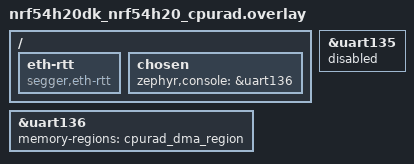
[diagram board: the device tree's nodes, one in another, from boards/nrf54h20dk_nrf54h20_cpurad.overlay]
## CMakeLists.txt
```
#
# Copyright (c) 2021 Nordic Semiconductor ASA
#
# SPDX-License-Identifier: LicenseRef-Nordic-5-Clause
#

cmake_minimum_required(VERSION 3.20.0)

find_package(Zephyr REQUIRED HINTS $ENV{ZEPHYR_BASE})

project(psa_tls_sample)

zephyr_include_directories(src ${COMMON_DIR})
target_include_directories(app PUBLIC ./include)
target_sources(app PRIVATE src/main.c
                           src/psa_tls_common.c)

if(CONFIG_BUILD_WITH_TFM)
  set(TLS_SRC_PATH "non-secure")
else()
  set(TLS_SRC_PATH "secure")
endif()

if(CONFIG_PSA_TLS_SAMPLE_TYPE_SERVER)
  target_sources(app PRIVATE src/${TLS_SRC_PATH}/psa_tls_credentials_server.c)
  if(CONFIG_NET_SOCKETS_ENABLE_DTLS)
    target_sources(app PRIVATE src/psa_dtls_functions_server.c)
  else()
    target_sources(app PRIVATE src/psa_tls_functions_server.c)
  endif()
else()
  target_sources(app PRIVATE src/${TLS_SRC_PATH}/psa_tls_credentials_client.c)
  if(CONFIG_NET_SOCKETS_ENABLE_DTLS)
    target_sources(app PRIVATE src/psa_dtls_functions_client.c)
  else()
    target_sources(app PRIVATE src/psa_tls_functions_client.c)
  endif()
endif()

set(gen_dir ${ZEPHYR_BINARY_DIR}/include/generated/)

if(CONFIG_PSA_WANT_ECC_SECP_R1_256)
  set(CURVE "_secp256r1")
elseif(CONFIG_PSA_WANT_ECC_SECP_R1_384)
  set(CURVE "_secp384r1")
endif()

if(CONFIG_PSA_TLS_CERTIFICATE_TYPE_RSA)
  set(CTYPE "rsa")
  set(CURVE "")
elseif(CONFIG_PSA_TLS_CERTIFICATE_TYPE_ECDSA)
  set(CTYPE "ec")
endif()


foreach(inc_file
  root-cert
  server-cert
  server-cert-key
)
  set(modified_inc_file "${CTYPE}-${inc_file}${CURVE}.der")
  generate_inc_file_for_target(
    app
    certs/${modified_inc_file}
    ${gen_dir}/${inc_file}.der.inc
  )
endforeach()
```

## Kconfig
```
#
# Copyright (c) 2021 Nordic Semiconductor
#
# SPDX-License-Identifier: LicenseRef-Nordic-5-Clause
#

source "Kconfig.zephyr"

menu "PSA TLS sample"

choice PSA_TLS_CERTIFICATE_TYPE
	prompt "RSA or ECDSA certifcates"
	default PSA_TLS_CERTIFICATE_TYPE_ECDSA

config PSA_TLS_CERTIFICATE_TYPE_RSA
	bool "Use RSA certificate in PSA TLS sample"
	help
	  Enable RSA certificates when testing ciphers that supports RSA for authentication.

config PSA_TLS_CERTIFICATE_TYPE_ECDSA
	bool "Use ECDSA certificate in PSA TLS sample"
	help
	  Enable ECDSA certificates when testing ciphers that supports ECDSA for authentication.

endchoice

choice PSA_TLS_SAMPLE_TYPE
	prompt "Server or Client selection"
	default PSA_TLS_SAMPLE_TYPE_SERVER

config PSA_TLS_SAMPLE_TYPE_SERVER
	bool "Enable Server functionality in PSA TLS sample"

config PSA_TLS_SAMPLE_TYPE_CLIENT
	bool "Enable Client functionality in PSA TLS sample"

endchoice

config NET_CONFIG_MY_IPV4_ADDR
	default "192.0.2.1" if PSA_TLS_SAMPLE_TYPE_SERVER
	default "192.0.2.2" if PSA_TLS_SAMPLE_TYPE_CLIENT

config NET_CONFIG_PEER_IPV4_ADDR
	default "192.0.2.2" if PSA_TLS_SAMPLE_TYPE_SERVER
	default "192.0.2.1" if PSA_TLS_SAMPLE_TYPE_CLIENT

endmenu
```

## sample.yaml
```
sample:
  description: |
    This app provides an example of performing TLS handshake as either server or client
  name: TLS Sample
tests:
  ################################################################################
  ## PSA APIs with Cryptocell and Oberon
  ################################################################################
  sample.psa_tls.tls_server.ecdsa.cc3xx_oberon:
    sysbuild: true
    build_only: true
    extra_args:
      EXTRA_CONF_FILE="overlays/server.conf;overlays/ecdsa.conf;overlays/cc3xx-oberon-psa.conf"
    platform_allow:
      - nrf5340dk/nrf5340/cpuapp
      - nrf9160dk/nrf9160
      - nrf5340dk/nrf5340/cpuapp/ns
      - nrf9160dk/nrf9160/ns
      - nrf9161dk/nrf9161
      - nrf9161dk/nrf9161/ns
      - nrf9151dk/nrf9151
      - nrf9151dk/nrf9151/ns
    integration_platforms:
      - nrf5340dk/nrf5340/cpuapp
      - nrf5340dk/nrf5340/cpuapp/ns
      - nrf9160dk/nrf9160
      - nrf9160dk/nrf9160/ns
      - nrf9161dk/nrf9161
      - nrf9161dk/nrf9161/ns
      - nrf9151dk/nrf9151
      - nrf9151dk/nrf9151/ns
    tags:
      - ci_build
      - cc3xx_oberon
      - sysbuild
      - ci_samples_crypto
  sample.psa_tls.dtls_server.ecdsa.cc3xx_oberon:
    sysbuild: true
    build_only: true
    extra_args:
      EXTRA_CONF_FILE="overlays/server.conf;overlays/ecdsa.conf;overlays/cc3xx-oberon-psa.conf;overlays/dtls.conf"
    platform_allow:
      - nrf5340dk/nrf5340/cpuapp
      - nrf5340dk/nrf5340/cpuapp/ns
      - nrf9160dk/nrf9160
      - nrf9160dk/nrf9160/ns
      - nrf9161dk/nrf9161
      - nrf9161dk/nrf9161/ns
      - nrf9151dk/nrf9151
      - nrf9151dk/nrf9151/ns
    integration_platforms:
      - nrf5340dk/nrf5340/cpuapp
      - nrf5340dk/nrf5340/cpuapp/ns
      - nrf9160dk/nrf9160
      - nrf9160dk/nrf9160/ns
      - nrf9161dk/nrf9161
      - nrf9161dk/nrf9161/ns
      - nrf9151dk/nrf9151
      - nrf9151dk/nrf9151/ns
    tags:
      - ci_build
      - dtls
      - cc3xx_oberon
      - sysbuild
      - ci_samples_crypto
  sample.psa_tls.tls_client.ecdsa.cc3xx_oberon:
    sysbuild: true
    build_only: true
    extra_args:
      EXTRA_CONF_FILE="overlays/client.conf;overlays/ecdsa.conf;overlays/cc3xx-oberon-psa.conf"
    platform_allow:
      - nrf5340dk/nrf5340/cpuapp
      - nrf5340dk/nrf5340/cpuapp/ns
      - nrf9160dk/nrf9160
      - nrf9160dk/nrf9160/ns
      - nrf9161dk/nrf9161
      - nrf9161dk/nrf9161/ns
      - nrf9151dk/nrf9151
      - nrf9151dk/nrf9151/ns
    integration_platforms:
      - nrf5340dk/nrf5340/cpuapp
      - nrf5340dk/nrf5340/cpuapp/ns
      - nrf9160dk/nrf9160
      - nrf9160dk/nrf9160/ns
      - nrf9161dk/nrf9161
      - nrf9161dk/nrf9161/ns
      - nrf9151dk/nrf9151
      - nrf9151dk/nrf9151/ns
    tags:
      - ci_build
      - cc3xx_oberon
      - sysbuild
      - ci_samples_crypto
  sample.psa_tls.dtls_client.ecdsa.cc3xx_oberon:
    sysbuild: true
    build_only: true
    extra_args:
      EXTRA_CONF_FILE="overlays/client.conf;overlays/ecdsa.conf;overlays/cc3xx-oberon-psa.conf;overlays/dtls.conf"
    platform_allow:
      - nrf5340dk/nrf5340/cpuapp
      - nrf5340dk/nrf5340/cpuapp/ns
      - nrf9160dk/nrf9160
      - nrf9160dk/nrf9160/ns
      - nrf9161dk/nrf9161
      - nrf9161dk/nrf9161/ns
      - nrf9151dk/nrf9151
      - nrf9151dk/nrf9151/ns
    integration_platforms:
      - nrf5340dk/nrf5340/cpuapp
      - nrf5340dk/nrf5340/cpuapp/ns
      - nrf9160dk/nrf9160
      - nrf9160dk/nrf9160/ns
      - nrf9161dk/nrf9161
      - nrf9161dk/nrf9161/ns
      - nrf9151dk/nrf9151
      - nrf9151dk/nrf9151/ns
    tags:
      - ci_build
      - dtls
      - cc3xx_oberon
      - sysbuild
      - ci_samples_crypto
  sample.psa_tls.tls_1_3_server.ecdsa.cc3xx_oberon:
    sysbuild: true
    build_only: true
    extra_args:
      EXTRA_CONF_FILE="overlays/server.conf;overlays/ecdsa.conf;overlays/cc3xx-oberon-psa.conf;overlays/tls_1_3.conf"
    platform_allow:
      - nrf5340dk/nrf5340/cpuapp
      - nrf5340dk/nrf5340/cpuapp/ns
      - nrf9160dk/nrf9160
      - nrf9160dk/nrf9160/ns
      - nrf9161dk/nrf9161
      - nrf9161dk/nrf9161/ns
      - nrf9151dk/nrf9151
      - nrf9151dk/nrf9151/ns
    integration_platforms:
      - nrf5340dk/nrf5340/cpuapp
      - nrf5340dk/nrf5340/cpuapp/ns
      - nrf9160dk/nrf9160
      - nrf9160dk/nrf9160/ns
      - nrf9161dk/nrf9161
      - nrf9161dk/nrf9161/ns
      - nrf9151dk/nrf9151
      - nrf9151dk/nrf9151/ns
    tags:
      - ci_build
      - cc3xx_oberon
      - sysbuild
      - ci_samples_crypto
  sample.psa_tls.tls_1_3_client.ecdsa.cc3xx_oberon:
    sysbuild: true
    build_only: true
    extra_args:
      EXTRA_CONF_FILE="overlays/client.conf;overlays/ecdsa.conf;overlays/cc3xx-oberon-psa.conf;overlays/tls_1_3.conf"
    platform_allow:
      - nrf5340dk/nrf5340/cpuapp
      - nrf5340dk/nrf5340/cpuapp/ns
      - nrf9160dk/nrf9160
      - nrf9160dk/nrf9160/ns
      - nrf9161dk/nrf9161
      - nrf9161dk/nrf9161/ns
      - nrf9151dk/nrf9151
      - nrf9151dk/nrf9151/ns
    integration_platforms:
      - nrf5340dk/nrf5340/cpuapp
      - nrf5340dk/nrf5340/cpuapp/ns
      - nrf9160dk/nrf9160
      - nrf9160dk/nrf9160/ns
      - nrf9161dk/nrf9161
      - nrf9161dk/nrf9161/ns
      - nrf9151dk/nrf9151
      - nrf9151dk/nrf9151/ns
    tags:
      - ci_build
      - cc3xx_oberon
      - sysbuild
      - ci_samples_crypto
  ################################################################################
  ## PSA APIs with Cracen
  ################################################################################
  sample.psa_tls.tls_server.ecdsa.cracen:
    sysbuild: true
    build_only: true
    extra_args:
      EXTRA_CONF_FILE="overlays/server.conf;overlays/ecdsa.conf;overlays/cracen-psa.conf"
    platform_allow:
      - nrf54l15dk/nrf54l15/cpuapp
      - nrf54l15dk/nrf54l15/cpuapp/ns
      - nrf54lm20pdk/nrf54lm20a/cpuapp
      - nrf54l15dk/nrf54l10/cpuapp
      - nrf54l15dk/nrf54l10/cpuapp/ns
      - nrf54h20dk/nrf54h20/cpuapp
      - nrf54h20dk/nrf54h20/cpurad
    integration_platforms:
      - nrf54l15dk/nrf54l15/cpuapp
      - nrf54l15dk/nrf54l15/cpuapp/ns
      - nrf54lm20pdk/nrf54lm20a/cpuapp
      - nrf54l15dk/nrf54l10/cpuapp
      - nrf54l15dk/nrf54l10/cpuapp/ns
      - nrf54h20dk/nrf54h20/cpuapp
      - nrf54h20dk/nrf54h20/cpurad
    tags:
      - ci_build
      - cracen
      - sysbuild
      - ci_samples_crypto
  sample.psa_tls.dtls_server.ecdsa.cracen:
    sysbuild: true
    build_only: true
    extra_args:
      EXTRA_CONF_FILE="overlays/server.conf;overlays/ecdsa.conf;overlays/cracen-psa.conf;overlays/dtls.conf"
    platform_allow:
      - nrf54l15dk/nrf54l15/cpuapp
      - nrf54l15dk/nrf54l15/cpuapp/ns
      - nrf54lm20pdk/nrf54lm20a/cpuapp
      - nrf54l15dk/nrf54l10/cpuapp
      - nrf54l15dk/nrf54l10/cpuapp/ns
      - nrf54h20dk/nrf54h20/cpuapp
      - nrf54h20dk/nrf54h20/cpurad
    integration_platforms:
      - nrf54l15dk/nrf54l15/cpuapp
      - nrf54l15dk/nrf54l15/cpuapp/ns
      - nrf54lm20pdk/nrf54lm20a/cpuapp
      - nrf54l15dk/nrf54l10/cpuapp
      - nrf54l15dk/nrf54l10/cpuapp/ns
      - nrf54h20dk/nrf54h20/cpuapp
      - nrf54h20dk/nrf54h20/cpurad
    tags:
      - ci_build
      - cracen
      - dtls
      - sysbuild
      - ci_samples_crypto
  sample.psa_tls.tls_client.ecdsa.cracen:
    sysbuild: true
    build_only: true
    extra_args:
      EXTRA_CONF_FILE="overlays/client.conf;overlays/ecdsa.conf;overlays/cracen-psa.conf"
    platform_allow:
      - nrf54l15dk/nrf54l15/cpuapp
      - nrf54l15dk/nrf54l15/cpuapp/ns
      - nrf54lm20pdk/nrf54lm20a/cpuapp
      - nrf54l15dk/nrf54l10/cpuapp
      - nrf54l15dk/nrf54l10/cpuapp/ns
      - nrf54h20dk/nrf54h20/cpuapp
      - nrf54h20dk/nrf54h20/cpurad
    integration_platforms:
      - nrf54l15dk/nrf54l15/cpuapp
      - nrf54l15dk/nrf54l15/cpuapp/ns
      - nrf54lm20pdk/nrf54lm20a/cpuapp
      - nrf54l15dk/nrf54l10/cpuapp
      - nrf54l15dk/nrf54l10/cpuapp/ns
      - nrf54h20dk/nrf54h20/cpuapp
      - nrf54h20dk/nrf54h20/cpurad
    tags:
      - ci_build
      - cracen
      - sysbuild
      - ci_samples_crypto
  sample.psa_tls.dtls_client.ecdsa.cracen:
    sysbuild: true
    build_only: true
    extra_args:
      EXTRA_CONF_FILE="overlays/client.conf;overlays/ecdsa.conf;overlays/cracen-psa.conf;overlays/dtls.conf"
    platform_allow:
      - nrf54l15dk/nrf54l15/cpuapp
      - nrf54l15dk/nrf54l15/cpuapp/ns
      - nrf54lm20pdk/nrf54lm20a/cpuapp
      - nrf54l15dk/nrf54l10/cpuapp
      - nrf54l15dk/nrf54l10/cpuapp/ns
      - nrf54h20dk/nrf54h20/cpuapp
      - nrf54h20dk/nrf54h20/cpurad
    integration_platforms:
      - nrf54l15dk/nrf54l15/cpuapp
      - nrf54l15dk/nrf54l15/cpuapp/ns
      - nrf54lm20pdk/nrf54lm20a/cpuapp
      - nrf54l15dk/nrf54l10/cpuapp
      - nrf54l15dk/nrf54l10/cpuapp/ns
      - nrf54h20dk/nrf54h20/cpuapp
      - nrf54h20dk/nrf54h20/cpurad
    tags:
      - ci_build
      - cracen
      - sysbuild
      - ci_samples_crypto
  sample.psa_tls.tls_server_secp384r1.ecdsa.cracen:
    sysbuild: true
    build_only: true
    extra_args:
      EXTRA_CONF_FILE="overlays/server.conf;overlays/ecdsa_secp384r1.conf;overlays/cracen-psa.conf"
    platform_allow:
      - nrf54l15dk/nrf54l15/cpuapp
      - nrf54l15dk/nrf54l15/cpuapp/ns
      - nrf54lm20pdk/nrf54lm20a/cpuapp
      - nrf54l15dk/nrf54l10/cpuapp
      - nrf54h20dk/nrf54h20/cpuapp
      - nrf54h20dk/nrf54h20/cpurad
    integration_platforms:
      - nrf54l15dk/nrf54l15/cpuapp
      - nrf54l15dk/nrf54l15/cpuapp/ns
      - nrf54lm20pdk/nrf54lm20a/cpuapp
      - nrf54l15dk/nrf54l10/cpuapp
      - nrf54h20dk/nrf54h20/cpuapp
      - nrf54h20dk/nrf54h20/cpurad
    tags:
      - ci_build
      - cracen
      - sysbuild
      - ci_samples_crypto
      - secp384r1
  sample.psa_tls.dtls_server_secp384r1.ecdsa.cracen:
    sysbuild: true
    build_only: true
    extra_args:
      EXTRA_CONF_FILE="overlays/server.conf;overlays/ecdsa_secp384r1.conf;overlays/cracen-psa.conf;overlays/dtls.conf"
    platform_allow:
      - nrf54l15dk/nrf54l15/cpuapp
      - nrf54l15dk/nrf54l15/cpuapp/ns
      - nrf54lm20pdk/nrf54lm20a/cpuapp
      - nrf54l15dk/nrf54l10/cpuapp
      - nrf54h20dk/nrf54h20/cpuapp
      - nrf54h20dk/nrf54h20/cpurad
    integration_platforms:
      - nrf54l15dk/nrf54l15/cpuapp
      - nrf54l15dk/nrf54l15/cpuapp/ns
      - nrf54lm20pdk/nrf54lm20a/cpuapp
      - nrf54l15dk/nrf54l10/cpuapp
      - nrf54h20dk/nrf54h20/cpuapp
      - nrf54h20dk/nrf54h20/cpurad
    tags:
      - ci_build
      - cracen
      - dtls
      - sysbuild
      - ci_samples_crypto
      - secp384r1
  sample.psa_tls.tls_client_secp384r1.ecdsa.cracen:
    sysbuild: true
    build_only: true
    extra_args:
      EXTRA_CONF_FILE="overlays/client.conf;overlays/ecdsa_secp384r1.conf;overlays/cracen-psa.conf"
    platform_allow:
      - nrf54l15dk/nrf54l15/cpuapp
      - nrf54l15dk/nrf54l15/cpuapp/ns
      - nrf54lm20pdk/nrf54lm20a/cpuapp
      - nrf54l15dk/nrf54l10/cpuapp
      - nrf54h20dk/nrf54h20/cpuapp
      - nrf54h20dk/nrf54h20/cpurad
    integration_platforms:
      - nrf54l15dk/nrf54l15/cpuapp
      - nrf54l15dk/nrf54l15/cpuapp/ns
      - nrf54lm20pdk/nrf54lm20a/cpuapp
      - nrf54l15dk/nrf54l10/cpuapp
      - nrf54h20dk/nrf54h20/cpuapp
      - nrf54h20dk/nrf54h20/cpurad
    tags:
      - ci_build
      - cracen
      - sysbuild
      - ci_samples_crypto
      - secp384r1
  sample.psa_tls.dtls_client_secp384r1.ecdsa.cracen:
    sysbuild: true
    build_only: true
    extra_args:
      EXTRA_CONF_FILE="overlays/client.conf;overlays/ecdsa_secp384r1.conf;overlays/cracen-psa.conf;overlays/dtls.conf"
    platform_allow:
      - nrf54l15dk/nrf54l15/cpuapp
      - nrf54l15dk/nrf54l15/cpuapp/ns
      - nrf54lm20pdk/nrf54lm20a/cpuapp
      - nrf54l15dk/nrf54l10/cpuapp
      - nrf54h20dk/nrf54h20/cpuapp
      - nrf54h20dk/nrf54h20/cpurad
    integration_platforms:
      - nrf54l15dk/nrf54l15/cpuapp
      - nrf54l15dk/nrf54l15/cpuapp/ns
      - nrf54lm20pdk/nrf54lm20a/cpuapp
      - nrf54l15dk/nrf54l10/cpuapp
      - nrf54h20dk/nrf54h20/cpuapp
      - nrf54h20dk/nrf54h20/cpurad
    tags:
      - ci_build
      - cracen
      - sysbuild
      - ci_samples_crypto
      - secp384r1
  sample.psa_tls.tls_1_3_server.ecdsa.cracen:
    sysbuild: true
    build_only: true
    extra_args:
      EXTRA_CONF_FILE="overlays/server.conf;overlays/ecdsa.conf;overlays/cracen-psa.conf;overlays/tls_1_3.conf"
    platform_allow:
      - nrf54l15dk/nrf54l15/cpuapp
      - nrf54l15dk/nrf54l15/cpuapp/ns
      - nrf54l15dk/nrf54l10/cpuapp
      - nrf54l15dk/nrf54l10/cpuapp/ns
      - nrf54h20dk/nrf54h20/cpuapp
      - nrf54h20dk/nrf54h20/cpurad
    integration_platforms:
      - nrf54l15dk/nrf54l15/cpuapp
      - nrf54l15dk/nrf54l15/cpuapp/ns
      - nrf54l15dk/nrf54l10/cpuapp
      - nrf54l15dk/nrf54l10/cpuapp/ns
      - nrf54h20dk/nrf54h20/cpuapp
      - nrf54h20dk/nrf54h20/cpurad
    tags:
      - ci_build
      - cracen
      - sysbuild
      - ci_samples_crypto
  sample.psa_tls.tls_1_3_client.ecdsa.cracen:
    sysbuild: true
    build_only: true
    extra_args:
      EXTRA_CONF_FILE="overlays/client.conf;overlays/ecdsa.conf;overlays/cracen-psa.conf;overlays/tls_1_3.conf"
    platform_allow:
      - nrf54l15dk/nrf54l15/cpuapp
      - nrf54l15dk/nrf54l15/cpuapp/ns
      - nrf54l15dk/nrf54l10/cpuapp
      - nrf54l15dk/nrf54l10/cpuapp/ns
      - nrf54h20dk/nrf54h20/cpuapp
      - nrf54h20dk/nrf54h20/cpurad
    integration_platforms:
      - nrf54l15dk/nrf54l15/cpuapp
      - nrf54l15dk/nrf54l15/cpuapp/ns
      - nrf54l15dk/nrf54l10/cpuapp
      - nrf54l15dk/nrf54l10/cpuapp/ns
      - nrf54h20dk/nrf54h20/cpuapp
      - nrf54h20dk/nrf54h20/cpurad
    tags:
      - ci_build
      - cracen
      - sysbuild
      - ci_samples_crypto
  ################################################################################
  ## PSA APIs with Cracen and Oberon
  ################################################################################
  sample.psa_tls.tls_1_3_server.ecdsa.cracen_oberon:
    sysbuild: true
    build_only: true
    extra_args:
      EXTRA_CONF_FILE="overlays/server.conf;overlays/ecdsa.conf;overlays/cracen-oberon-psa.conf;overlays/tls_1_3.conf"
    platform_allow:
      - nrf54l15dk/nrf54l15/cpuapp
      - nrf54l15dk/nrf54l15/cpuapp/ns
      - nrf54lm20pdk/nrf54lm20a/cpuapp
      - nrf54l15dk/nrf54l10/cpuapp
      - nrf54l15dk/nrf54l10/cpuapp/ns
    integration_platforms:
      - nrf54l15dk/nrf54l15/cpuapp
      - nrf54l15dk/nrf54l15/cpuapp/ns
      - nrf54lm20pdk/nrf54lm20a/cpuapp
      - nrf54l15dk/nrf54l10/cpuapp
      - nrf54l15dk/nrf54l10/cpuapp/ns
    tags:
      - ci_build
      - cracen_oberon
      - sysbuild
      - ci_samples_crypto
  sample.psa_tls.tls_1_3_client.ecdsa.cracen_oberon:
    sysbuild: true
    build_only: true
    extra_args:
      EXTRA_CONF_FILE="overlays/client.conf;overlays/ecdsa.conf;overlays/cracen-oberon-psa.conf;overlays/tls_1_3.conf"
    platform_allow:
      - nrf54l15dk/nrf54l15/cpuapp
      - nrf54l15dk/nrf54l15/cpuapp/ns
      - nrf54lm20pdk/nrf54lm20a/cpuapp
      - nrf54l15dk/nrf54l10/cpuapp
      - nrf54l15dk/nrf54l10/cpuapp/ns
    integration_platforms:
      - nrf54l15dk/nrf54l15/cpuapp
      - nrf54l15dk/nrf54l15/cpuapp/ns
      - nrf54lm20pdk/nrf54lm20a/cpuapp
      - nrf54l15dk/nrf54l10/cpuapp
      - nrf54l15dk/nrf54l10/cpuapp/ns
    tags:
      - ci_build
      - cracen_oberon
      - sysbuild
      - ci_samples_crypto
  ################################################################################
  ## Legacy APIs with Cryptocell (secure-only)
  ################################################################################
  sample.psa_tls.tls_server.rsa.cc3xx_legacy:
    sysbuild: true
    build_only: true
    extra_args:
      EXTRA_CONF_FILE="overlays/server.conf;overlays/rsa.conf;overlays/cc3xx-legacy.conf"
    platform_allow:
      - nrf52840dk/nrf52840
      - nrf9160dk/nrf9160
      - nrf5340dk/nrf5340/cpuapp
      - nrf9151dk/nrf9151
    integration_platforms:
      - nrf52840dk/nrf52840
      - nrf5340dk/nrf5340/cpuapp
      - nrf9160dk/nrf9160
      - nrf9151dk/nrf9151
    tags:
      - ci_build
      - legacy
      - cc3xx_legacy
      - sysbuild
      - ci_samples_crypto
  sample.psa_tls.tls_client.rsa.cc3xx_legacy:
    sysbuild: true
    build_only: true
    extra_args:
      EXTRA_CONF_FILE="overlays/client.conf;overlays/rsa.conf;overlays/cc3xx-legacy.conf"
    platform_allow:
      - nrf52840dk/nrf52840
      - nrf9160dk/nrf9160
      - nrf5340dk/nrf5340/cpuapp
      - nrf9151dk/nrf9151
    integration_platforms:
      - nrf52840dk/nrf52840
      - nrf5340dk/nrf5340/cpuapp
      - nrf9160dk/nrf9160
      - nrf9151dk/nrf9151
    tags:
      - ci_build
      - legacy
      - cc3xx_legacy
      - sysbuild
      - ci_samples_crypto
  sample.psa_tls.tls_server.ecdsa.cc3xx_legacy:
    sysbuild: true
    build_only: true
    extra_args:
      EXTRA_CONF_FILE="overlays/server.conf;overlays/ecdsa.conf;overlays/cc3xx-legacy.conf"
    platform_allow:
      - nrf52840dk/nrf52840
      - nrf9160dk/nrf9160
      - nrf5340dk/nrf5340/cpuapp
      - nrf9151dk/nrf9151
    integration_platforms:
      - nrf52840dk/nrf52840
      - nrf5340dk/nrf5340/cpuapp
      - nrf9160dk/nrf9160
      - nrf9151dk/nrf9151
    tags:
      - ci_build
      - legacy
      - cc3xx_legacy
      - sysbuild
      - ci_samples_crypto
  sample.psa_tls.tls_client.ecdsa.cc3xx_legacy:
    sysbuild: true
    build_only: true
    extra_args:
      EXTRA_CONF_FILE="overlays/client.conf;overlays/ecdsa.conf;overlays/cc3xx-legacy.conf"
    platform_allow:
      - nrf52840dk/nrf52840
      - nrf9160dk/nrf9160
      - nrf5340dk/nrf5340/cpuapp
      - nrf9151dk/nrf9151
    integration_platforms:
      - nrf52840dk/nrf52840
      - nrf5340dk/nrf5340/cpuapp
      - nrf9160dk/nrf9160
      - nrf9151dk/nrf9151
    tags:
      - ci_build
      - legacy
      - cc3xx_legacy
      - sysbuild
      - ci_samples_crypto
  ################################################################################
  ## Legacy APIs with Oberon (secure-only)
  ################################################################################
  sample.psa_tls.tls_server.rsa.oberon_legacy:
    sysbuild: true
    build_only: true
    extra_args:
      EXTRA_CONF_FILE="overlays/server.conf;overlays/rsa.conf;overlays/oberon-legacy.conf"
    platform_allow:
      - nrf52840dk/nrf52840
      - nrf9160dk/nrf9160
      - nrf5340dk/nrf5340/cpuapp
      - nrf9151dk/nrf9151
    integration_platforms:
      - nrf52840dk/nrf52840
      - nrf5340dk/nrf5340/cpuapp
      - nrf9160dk/nrf9160
      - nrf9151dk/nrf9151
    tags:
      - ci_build
      - legacy
      - oberon_legacy
      - sysbuild
      - ci_samples_crypto
  sample.psa_tls.tls_client.rsa.oberon_legacy:
    sysbuild: true
    build_only: true
    extra_args:
      EXTRA_CONF_FILE="overlays/client.conf;overlays/rsa.conf;overlays/oberon-legacy.conf"
    platform_allow:
      - nrf52840dk/nrf52840
      - nrf9160dk/nrf9160
      - nrf5340dk/nrf5340/cpuapp
      - nrf9151dk/nrf9151
    integration_platforms:
      - nrf52840dk/nrf52840
      - nrf5340dk/nrf5340/cpuapp
      - nrf9160dk/nrf9160
      - nrf9151dk/nrf9151
    tags:
      - ci_build
      - legacy
      - oberon_legacy
      - sysbuild
      - ci_samples_crypto
  sample.psa_tls.tls_server.ecdsa.oberon_legacy:
    sysbuild: true
    build_only: true
    extra_args:
      EXTRA_CONF_FILE="overlays/server.conf;overlays/ecdsa.conf;overlays/oberon-legacy.conf"
    platform_allow:
      - nrf52840dk/nrf52840
      - nrf9160dk/nrf9160
      - nrf5340dk/nrf5340/cpuapp
      - nrf9151dk/nrf9151
    integration_platforms:
      - nrf52840dk/nrf52840
      - nrf5340dk/nrf5340/cpuapp
      - nrf9160dk/nrf9160
      - nrf9151dk/nrf9151
    tags:
      - ci_build
      - legacy
      - oberon_legacy
      - sysbuild
      - ci_samples_crypto
  sample.psa_tls.tls_client.ecdsa.oberon_legacy:
    sysbuild: true
    build_only: true
    extra_args:
      EXTRA_CONF_FILE="overlays/client.conf;overlays/ecdsa.conf;overlays/oberon-legacy.conf"
    platform_allow:
      - nrf52840dk/nrf52840
      - nrf9160dk/nrf9160
      - nrf5340dk/nrf5340/cpuapp
      - nrf9151dk/nrf9151
    integration_platforms:
      - nrf52840dk/nrf52840
      - nrf5340dk/nrf5340/cpuapp
      - nrf9160dk/nrf9160
      - nrf9151dk/nrf9151
    tags:
      - ci_build
      - legacy
      - oberon_legacy
      - sysbuild
      - ci_samples_crypto
```

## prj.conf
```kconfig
#
# Copyright (c) 2021 Nordic Semiconductor ASA
#
# SPDX-License-Identifier: LicenseRef-Nordic-5-Clause
#

# Main thread
CONFIG_MAIN_STACK_SIZE=8192

# Logging
CONFIG_LOG=y
CONFIG_PRINTK=y
CONFIG_NET_LOG=y
CONFIG_LOG_DEFAULT_LEVEL=3
CONFIG_LOG_MODE_IMMEDIATE=y
CONFIG_LOG_ALWAYS_RUNTIME=y

# Networking
CONFIG_NETWORKING=y
CONFIG_NET_UDP=n
CONFIG_NET_TCP=y
CONFIG_NET_IPV6=n
CONFIG_NET_IPV4=y
CONFIG_NET_SOCKETS=y
CONFIG_NET_TCP_ISN_RFC6528=n
CONFIG_NET_CONFIG_SETTINGS=y
CONFIG_NET_CONFIG_NEED_IPV6=n
CONFIG_NET_CONFIG_NEED_IPV4=y
CONFIG_POSIX_API=y
CONFIG_NET_CONNECTION_MANAGER=n
CONFIG_NET_CONTEXT_NET_PKT_POOL=y

# TLS networking
CONFIG_ZVFS_OPEN_MAX=8
CONFIG_NET_SOCKETS_SOCKOPT_TLS=y
CONFIG_NET_SOCKETS_ENABLE_DTLS=n
CONFIG_NET_SOCKETS_TLS_MAX_CONTEXTS=6
CONFIG_NET_SOCKETS_TLS_MAX_CIPHERSUITES=16

# Network buffers
CONFIG_NET_MAX_CONTEXTS=6
CONFIG_NET_PKT_RX_COUNT=16
CONFIG_NET_PKT_TX_COUNT=16
CONFIG_NET_BUF_RX_COUNT=100
CONFIG_NET_BUF_TX_COUNT=100

# mbed TLS and security
CONFIG_MBEDTLS_PK_C=y

CONFIG_MBEDTLS_ENABLE_HEAP=y
CONFIG_MBEDTLS_HEAP_SIZE=32768
CONFIG_MBEDTLS_SSL_IN_CONTENT_LEN=2304
CONFIG_MBEDTLS_SSL_OUT_CONTENT_LEN=2304
CONFIG_MBEDTLS_SSL_CLI_C=y
CONFIG_MBEDTLS_TLS_LIBRARY=y
CONFIG_MBEDTLS_X509_LIBRARY=y

# NB: This list of PSA dependencies may be too long
CONFIG_PSA_WANT_GENERATE_RANDOM=y
CONFIG_PSA_WANT_KEY_TYPE_AES=y
CONFIG_PSA_WANT_ALG_CCM=y
CONFIG_PSA_WANT_ALG_GCM=y
CONFIG_PSA_WANT_ALG_CHACHA20_POLY1305=y
CONFIG_PSA_WANT_ALG_CMAC=y
CONFIG_PSA_WANT_ALG_HMAC=y
CONFIG_PSA_WANT_ALG_SHA_1=y
CONFIG_PSA_WANT_ALG_SHA_224=y
CONFIG_PSA_WANT_ALG_SHA_256=y
CONFIG_PSA_WANT_ALG_SHA_384=y
CONFIG_PSA_WANT_ALG_SHA_512=y
CONFIG_PSA_WANT_ALG_ECB_NO_PADDING=y
CONFIG_PSA_WANT_ALG_CBC_NO_PADDING=y
CONFIG_PSA_WANT_ALG_CBC_PKCS7=y
CONFIG_PSA_WANT_ALG_CTR=y
CONFIG_PSA_WANT_ALG_HKDF=y
CONFIG_PSA_WANT_ALG_TLS12_PRF=y
CONFIG_PSA_WANT_ALG_ECDH=y
CONFIG_PSA_WANT_ALG_ECDSA=y
CONFIG_PSA_WANT_ALG_DETERMINISTIC_ECDSA=y
CONFIG_PSA_WANT_ALG_JPAKE=y
CONFIG_PSA_WANT_ECC_SECP_R1_256=y
CONFIG_PSA_WANT_KEY_TYPE_ECC_KEY_PAIR_IMPORT=y
CONFIG_PSA_WANT_KEY_TYPE_ECC_KEY_PAIR_EXPORT=y
CONFIG_PSA_WANT_KEY_TYPE_ECC_KEY_PAIR_DERIVE=y
CONFIG_PSA_WANT_KEY_TYPE_ECC_KEY_PAIR_GENERATE=y
CONFIG_PSA_WANT_ALG_STREAM_CIPHER=y
CONFIG_PSA_WANT_KEY_TYPE_CHACHA20=y
CONFIG_PSA_WANT_ALG_TLS12_PSK_TO_MS=y

# RTT ethernet driver
CONFIG_ETH_RTT=y

# Optimizations
CONFIG_SPEED_OPTIMIZATIONS=y
```

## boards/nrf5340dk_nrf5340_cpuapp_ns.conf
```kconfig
#
# Copyright (c) 2024 Nordic Semiconductor ASA
#
# SPDX-License-Identifier: LicenseRef-Nordic-5-Clause
#
CONFIG_TFM_PROFILE_TYPE_NOT_SET=y
CONFIG_NRF_ENABLE_ICACHE=n
CONFIG_MBEDTLS_USE_PSA_CRYPTO=y
CONFIG_MBEDTLS_PSA_CRYPTO_C=y

CONFIG_PM_PARTITION_SIZE_TFM=0x60000
```

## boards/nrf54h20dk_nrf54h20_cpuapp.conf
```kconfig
#
# Copyright (c) 2024 Nordic Semiconductor
#
# SPDX-License-Identifier: LicenseRef-Nordic-5-Clause
#

# Disable Oberon PSA crypto drivers
CONFIG_PSA_CRYPTO_DRIVER_OBERON=n

# Enable PSA crypto from SSF client
CONFIG_PSA_SSF_CRYPTO_CLIENT=y
CONFIG_SSF_PSA_CRYPTO_SERVICE_ENABLED=y
```

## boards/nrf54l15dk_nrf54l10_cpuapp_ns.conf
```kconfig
#
# Copyright (c) 2025 Nordic Semiconductor ASA
#
# SPDX-License-Identifier: LicenseRef-Nordic-5-Clause
#
CONFIG_TFM_PROFILE_TYPE_NOT_SET=y
CONFIG_NRF_ENABLE_ICACHE=n
CONFIG_MBEDTLS_USE_PSA_CRYPTO=y
CONFIG_MBEDTLS_PSA_CRYPTO_C=y

# The ECDSA CA certificate is stored persistently with Protected Storage,
# which internally uses Internal Trusted Storage. Since ITS encryption is
# enabled by default for nRF54L10, the sample must be configured with a
# larger ITS asset size than the default 500 bytes. This is because
# encrypted ITS assets must be stored in a single chunk.
CONFIG_TFM_ITS_MAX_ASSET_SIZE_OVERRIDE=y
CONFIG_TFM_ITS_MAX_ASSET_SIZE=600
```

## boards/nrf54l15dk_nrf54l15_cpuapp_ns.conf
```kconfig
#
# Copyright (c) 2024 Nordic Semiconductor ASA
#
# SPDX-License-Identifier: LicenseRef-Nordic-5-Clause
#
CONFIG_TFM_PROFILE_TYPE_NOT_SET=y
CONFIG_NRF_ENABLE_ICACHE=n
CONFIG_MBEDTLS_USE_PSA_CRYPTO=y
CONFIG_MBEDTLS_PSA_CRYPTO_C=y

# The ECDSA CA certificate is stored persistently with Protected Storage,
# which internally uses Internal Trusted Storage. Since ITS encryption is
# enabled by default for nRF54L15, the sample must be configured with a
# larger ITS asset size than the default 500 bytes. This is because
# encrypted ITS assets must be stored in a single chunk.
CONFIG_TFM_ITS_MAX_ASSET_SIZE_OVERRIDE=y
CONFIG_TFM_ITS_MAX_ASSET_SIZE=600
```

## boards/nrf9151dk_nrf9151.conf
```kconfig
#
# Copyright (c) 2024 Nordic Semiconductor ASA
#
# SPDX-License-Identifier: LicenseRef-Nordic-5-Clause
#
CONFIG_SRAM_SIZE=256
```

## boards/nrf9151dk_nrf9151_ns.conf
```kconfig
#
# Copyright (c) 2024 Nordic Semiconductor ASA
#
# SPDX-License-Identifier: LicenseRef-Nordic-5-Clause
#
CONFIG_TFM_PROFILE_TYPE_NOT_SET=y
CONFIG_NRF_ENABLE_ICACHE=n
CONFIG_MBEDTLS_USE_PSA_CRYPTO=y
CONFIG_MBEDTLS_PSA_CRYPTO_C=y

CONFIG_NRF_MODEM_LIB=n
CONFIG_PM_PARTITION_SIZE_TFM_SRAM=0x18000
CONFIG_PM_PARTITION_SIZE_TFM=0x60000
CONFIG_FPU=y
```

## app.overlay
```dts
/*
 * Copyright (c) 2021 Nordic Semiconductor ASA
 *
 * SPDX-License-Identifier: LicenseRef-Nordic-5-Clause
 */

/ {
	eth-rtt {
		compatible = "segger,eth-rtt";
	};
};
```

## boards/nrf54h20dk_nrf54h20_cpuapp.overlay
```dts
/*
 * Copyright (c) 2024 Nordic Semiconductor ASA
 *
 * SPDX-License-Identifier: LicenseRef-Nordic-5-Clause
 */

/ {
	eth-rtt {
		compatible = "segger,eth-rtt";
	};
};
```

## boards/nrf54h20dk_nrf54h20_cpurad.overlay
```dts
/*
 * Copyright (c) 2024 Nordic Semiconductor ASA
 *
 * SPDX-License-Identifier: LicenseRef-Nordic-5-Clause
 */
/ {
	eth-rtt {
		compatible = "segger,eth-rtt";
	};

	chosen {
		zephyr,console = &uart136;
	};
};


&uart136 {
	status = "okay";
	memory-regions = <&cpurad_dma_region>;
};

&uart135 {
	status = "disabled";
};
```

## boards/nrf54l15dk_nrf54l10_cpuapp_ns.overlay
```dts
/*
 * Copyright (c) 2025 Nordic Semiconductor
 *
 * SPDX-License-Identifier: LicenseRef-Nordic-5-Clause
 */

&rram_controller {
	/delete-node/ cpuflpr_sram;
	/delete-node/ cpuflpr_rram;
};

/* Adjust the cpuapp_sram to include the freed up cpuflpr_sram */
&cpuapp_sram {
	reg = <0x20000000 DT_SIZE_K(192)>;
	ranges = <0x0 0x20000000 0x20030000>;
};

/* Adjust the cpuapp_rram to include the freed up cpuflpr_rram */
&cpuapp_rram {
	reg = <0x0 DT_SIZE_K(1024)>;
};

/ {
	eth-rtt {
		compatible = "segger,eth-rtt";
	};
};
```

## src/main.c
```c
/*
 * Copyright (c) 2021 Nordic Semiconductor ASA.
 *
 * SPDX-License-Identifier: LicenseRef-Nordic-5-Clause
 */

#include <nrf.h>
#include <zephyr/kernel.h>
#include <zephyr/logging/log.h>
#include <zephyr/net/tls_credentials.h>
#include "psa_tls_functions.h"
#include "psa_tls_credentials.h"
#include "certificate.h"
#include "dummy_psk.h"
#include "psa/crypto.h"

LOG_MODULE_REGISTER(psa_tls_sample);


static int tls_set_preshared_key(void)
{
	LOG_INF("Registering Pre-shared key");

	int err = tls_credential_add(PSK_TAG, TLS_CREDENTIAL_PSK,
				     psk, sizeof(psk));
	if (err < 0) {
		LOG_ERR("Failed to register PSK: %d", err);
		return err;
	}
	err = tls_credential_add(PSK_TAG, TLS_CREDENTIAL_PSK_ID,
				 psk_id, strlen(psk_id));
	if (err < 0) {
		LOG_ERR("Failed to register PSK ID: %d", err);
		return err;
	}

	return APP_SUCCESS;
}


int main(void)
{
	int err;

	LOG_INF("PSA TLS app started");

#if defined(MBEDTLS_USE_PSA_CRYPTO)
	err = psa_crypto_init();
	if (err < 0) {
		return APP_ERROR;
	}
#endif

	err = tls_set_credentials();
	if (err < 0) {
		return APP_ERROR;
	}

	err = tls_set_preshared_key();
	if (err < 0) {
		return APP_ERROR;
	}

	process_psa_tls();

	return APP_SUCCESS;
}
```

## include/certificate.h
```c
/*
 * Copyright (c) 2021 Nordic Semiconductor ASA.
 *
 * SPDX-License-Identifier: LicenseRef-Nordic-5-Clause
 */

#ifndef __CERTIFICATE_H__
#define __CERTIFICATE_H__

#define CA_CERTIFICATE_TAG 1
#define SERVER_CERTIFICATE_TAG 2
#define PSK_TAG 3


static const unsigned char ca_certificate[] = {
#include "root-cert.der.inc"
};
static const unsigned char server_certificate[] = {
#include "server-cert.der.inc"
};
/* This is the private key in pkcs#8 format. */
static const unsigned char private_key[] = {
#include "server-cert-key.der.inc"
};

#endif /* __CERTIFICATE_H__ */
```

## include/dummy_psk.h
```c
/*
 * Copyright (c) 2021 Nordic Semiconductor ASA.
 *
 * SPDX-License-Identifier: LicenseRef-Nordic-5-Clause
 */

#ifndef __DUMMY_PSK_H__
#define __DUMMY_PSK_H__

static const unsigned char psk[] = {0x01, 0x01, 0x02, 0x03, 0x04, 0x05, 0x06,
0x07, 0x08, 0x09, 0x0a, 0x0b, 0x0c, 0x0d, 0x0e, 0x0f};
static const char psk_id[] = "PSK_identity";

#endif /* __DUMMY_PSK_H__ */
```

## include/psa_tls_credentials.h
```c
/*
 * Copyright (c) 2021 Nordic Semiconductor ASA.
 *
 * SPDX-License-Identifier: LicenseRef-Nordic-5-Clause
 */

#ifndef TLS_CREDENTIALS_H__
#define TLS_CREDENTIALS_H__

#ifdef __cplusplus
extern "C" {
#endif


#define PSA_PS_CERTIFICATE_UID		(1)
#define PSA_PS_CERTIFICATE_KEY_UID	(2)
#define PSA_PS_CA_CERTIFICATE_UID	(3)

#define APP_SUCCESS			(0)
#define APP_ERROR			(-1)


/** @brief Function for registering certificates and PSKs.
 *
 * @retval 0 TLS credential successfully set.
 */
int tls_set_credentials(void);


#ifdef __cplusplus
}
#endif

#endif /* TLS_CREDENTIALS_H__ */
```

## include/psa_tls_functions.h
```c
/*
 * Copyright (c) 2021 Nordic Semiconductor ASA.
 *
 * SPDX-License-Identifier: LicenseRef-Nordic-5-Clause
 */

#ifndef TLS_FUNCTIONS_H__
#define TLS_FUNCTIONS_H__

#ifdef __cplusplus
extern "C" {
#endif


#define SERVER_PORT 4243		/* The port number the TLS server will use. */
#define RECV_BUFFER_SIZE 2400		/* Receive-buffer size in bytes. */
#define MAX_CLIENT_QUEUE 1		/* Max number of connections in listen queue. */
#define TLS_PEER_HOSTNAME "localhost"	/* Peer TLS hostname when functioning as client. */


/** @brief Function for starting a TLS or a DTLS thread.
 *
 */
void process_psa_tls(void);

/** @brief Function for starting a TLS or a DTLS thread.
 *
 */
int psa_tls_send_buffer(int sock, const uint8_t *buf, size_t len);


#ifdef __cplusplus
}
#endif

#endif /* TLS_FUNCTIONS_H__ */
```

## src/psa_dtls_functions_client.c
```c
/*
 * Copyright (c) 2023 Nordic Semiconductor ASA.
 *
 * SPDX-License-Identifier: LicenseRef-Nordic-5-Clause
 */

#include <zephyr/logging/log.h>
LOG_MODULE_REGISTER(psa_dtls_client);

#include <nrf.h>
#include <errno.h>
#include <zephyr/kernel.h>
#include <zephyr/net/socket.h>
#include <zephyr/net/net_core.h>
#include <zephyr/net/tls_credentials.h>
#include <zephyr/linker/sections.h>

#include "certificate.h"
#include "psa_tls_functions.h"
#include "psa_tls_credentials.h"

static char recv_buffer[RECV_BUFFER_SIZE]; /* Buffer for storing payload */

/** @brief Function for setting up the client socket to use for DTLS handshake.
 *
 * @returns The socket identifier.
 */
static int setup_dtls_client_socket(void)
{
	int err;
	int sock;
	int verify = TLS_PEER_VERIFY_REQUIRED;

	/* List of security tags to register. */
	sec_tag_t sec_tag_list[] = {
		CA_CERTIFICATE_TAG,
		PSK_TAG,
	};

	sock = socket(AF_INET, SOCK_DGRAM, IPPROTO_DTLS_1_2);
	if (sock < 0) {
		LOG_ERR("Failed to create a DTLS socket. Err: %d", errno);
		return -errno;
	}

	err = setsockopt(sock, SOL_TLS, TLS_PEER_VERIFY, &verify, sizeof(verify));
	if (err < 0) {
		LOG_ERR("Failed to set DTLS peer verification. Err %d", errno);
		(void)close(sock);
		return -errno;
	}

	err = setsockopt(sock, SOL_TLS, TLS_SEC_TAG_LIST, sec_tag_list, sizeof(sec_tag_list));
	if (err < 0) {
		LOG_ERR("Failed to set DTLS security TAG list. Err: %d", errno);
		(void)close(sock);
		return -errno;
	}

	err = setsockopt(sock, SOL_TLS, TLS_HOSTNAME, TLS_PEER_HOSTNAME, sizeof(TLS_PEER_HOSTNAME));
	if (err < 0) {
		LOG_ERR("Failed to set TLS_HOSTNAME option. Err: %d", errno);
		(void)close(sock);
		return -errno;
	}

	return sock;
}

/** @brief Function that handles all the steps of the DTLS handshake for
 *  a client. Loops forever and connects on given port number.
 *
 */
void process_psa_tls(void)
{
	int ret;
	int sock;
	int received = 0;
	bool connected;
	struct sockaddr_in server_addr;
	socklen_t server_addr_len = sizeof(server_addr);

	server_addr.sin_family = AF_INET;
	server_addr.sin_port = htons(SERVER_PORT);
	inet_pton(AF_INET, CONFIG_NET_CONFIG_PEER_IPV4_ADDR, &server_addr.sin_addr);

	while (true) {
		connected = false;

		sock = setup_dtls_client_socket();
		if (sock < 0) {
			LOG_INF("Retrying acquiring socket");
			k_sleep(K_MSEC(1000));
			continue;
		}

		LOG_INF("Initiates DTLS connection on port %d ...", SERVER_PORT);
		ret = connect(sock, (struct sockaddr *)&server_addr, server_addr_len);
		if (ret != 0) {
			LOG_WRN("Cannot make DTLS connection. Err: %d", errno);
			LOG_INF("Will re-try connection in 1 second");
			(void)close(sock);
			k_sleep(K_MSEC(1000));
			continue;
		}

		/* Send one byte to trigger handshake */
		ret = psa_tls_send_buffer(sock, recv_buffer, 1);
		if (ret != 0) {
			LOG_INF("Not connected yet. Will re-try initiating handshake in 1 second");
			(void)close(sock);
			k_sleep(K_MSEC(1000));
			continue;
		}

		while (!connected) {
			/* Try to receive data to confirm connection */
			received = recv(sock, recv_buffer, sizeof(recv_buffer), 0);

			if (received == 0) {
				/* Connection closed */
				LOG_INF("DTLS Connection closed");
				break;

			} else if (received < 0) {
				/* Not connected error is expected */
				if (errno == ENOTCONN || errno == EWOULDBLOCK) {
					LOG_INF("Not connected yet. Will re-try receive in 1 "
						"second");
					k_sleep(K_MSEC(1000));
					continue;
				}

				/* Socket error */
				LOG_ERR("DTLS Connection error: %d", errno);
				break;
			}

			connected = true;
			break;
		}

		if (connected) {
			LOG_INF("DTLS handshake completed");
			LOG_INF("DTLS received %d byte(s)", received);

			ret = psa_tls_send_buffer(sock, recv_buffer, received);
			if (ret != 0) {
				LOG_ERR("DTLS Failed to send. Err: %d", errno);
			} else {
				LOG_INF("DTLS replied with %d bytes", received);
				LOG_INF("Closing DTLS connection");
			}
		}

		(void)close(sock);
	}
}
```

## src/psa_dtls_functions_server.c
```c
/*
 * Copyright (c) 2023 Nordic Semiconductor ASA.
 *
 * SPDX-License-Identifier: LicenseRef-Nordic-5-Clause
 */

#include <zephyr/logging/log.h>
LOG_MODULE_REGISTER(psa_dtls_server);

#include <nrf.h>
#include <errno.h>
#include <zephyr/kernel.h>
#include <zephyr/net/socket.h>
#include <zephyr/net/net_core.h>
#include <zephyr/net/tls_credentials.h>
#include <zephyr/linker/sections.h>

#include "certificate.h"
#include "psa_tls_functions.h"
#include "psa_tls_credentials.h"

static char recv_buffer[RECV_BUFFER_SIZE]; /* Buffer for storing payload */

/** @brief Function for setting up the server socket to use for DTLS handshake.
 *
 * @returns The socket identifier.
 */
static int setup_dtls_server_socket(void)
{
	int err;
	int sock;
	struct sockaddr_in my_addr;

	/* List of security tags to register. */
	sec_tag_t sec_tag_list[] = {
		SERVER_CERTIFICATE_TAG,
		PSK_TAG,
	};

	memset(&my_addr, 0, sizeof(my_addr));
	my_addr.sin_family = AF_INET;
	my_addr.sin_port = htons(SERVER_PORT);

	sock = socket(my_addr.sin_family, SOCK_DGRAM, IPPROTO_DTLS_1_2);
	if (sock < 0) {
		LOG_ERR("Failed to create a DTLS socket. Err: %d", errno);
		return -errno;
	}

	err = setsockopt(sock, SOL_TLS, TLS_SEC_TAG_LIST, sec_tag_list, sizeof(sec_tag_list));
	if (err < 0) {
		LOG_ERR("Failed to set DTLS security TAG list. Err: %d", errno);
		(void)close(sock);
		return -errno;
	}

	int role = TLS_DTLS_ROLE_SERVER;

	err = setsockopt(sock, SOL_TLS, TLS_DTLS_ROLE, &role, sizeof(role));
	if (err < 0) {
		LOG_ERR("Failed to set DTLS role secure option: %d", errno);
		(void)close(sock);
		return -errno;
	}

	err = bind(sock, (struct sockaddr *)&my_addr, sizeof(my_addr));
	if (err < 0) {
		LOG_ERR("Failed to bind DTLS socket. Err: %d", errno);
		(void)close(sock);
		return -errno;
	}

	return sock;
}

/** @brief Function that handles all the steps of the DTLS handshake for
 *  a server. Loops forever and accepts connections on the given port number.
 *
 */
void process_psa_tls(void)
{
	int ret;
	int client;
	int received = 0;
	struct sockaddr client_addr;
	socklen_t client_addr_len = sizeof(client_addr);

	while (true) {
		client = setup_dtls_server_socket();
		if (client < 0) {
			LOG_INF("Retrying to create a socket");
			k_sleep(K_MSEC(1000));
			continue;
		}

		LOG_INF("Waiting for DTLS connection on port %d ...", SERVER_PORT);

		while (true) {
			/* Try to receive data while connected */
			received = recvfrom(client, recv_buffer, sizeof(recv_buffer), 0,
					    &client_addr, &client_addr_len);

			if (received == 0) {
				/* Connection closed */
				LOG_INF("DTLS Connection closed");
				break;

			} else if (received < 0) {
				/* Socket error */
				LOG_ERR("DTLS Connection error: %d", errno);
				break;
			}

			LOG_INF("DTLS received %d bytes", received);

			ret = psa_tls_send_buffer(client, recv_buffer, received);
			if (ret != 0) {
				LOG_ERR("DTLS Failed to send. Err: %d", errno);
				break;
			}

			LOG_INF("DTLS replied with %d bytes", received);
		}

		LOG_INF("Closing DTLS connection");
		(void)close(client);
	}
}
```

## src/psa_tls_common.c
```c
/*
 * Copyright (c) 2021 Nordic Semiconductor ASA.
 *
 * SPDX-License-Identifier: LicenseRef-Nordic-5-Clause
 */

#include <nrf.h>
#include <errno.h>
#include <zephyr/kernel.h>
#include <zephyr/net/socket.h>

/** @brief Function for sending all data in a given buffer to a connected
 * socket.
 *
 * @param   sock        The socket identifier to send data to.
 * @param   buf         Pointer to the data buffer.
 * @param   len         Number of bytes to send from buf.
 *
 * @returns 0 on success.
 */
int psa_tls_send_buffer(int sock, const uint8_t *buf, size_t len)
{
	ssize_t sent_len;

	while (len > 0) {
		sent_len = send(sock, buf, len, 0);
		if (sent_len < 0) {
			return -errno;
		}

		buf += sent_len;
		len -= sent_len;
	}

	return 0;
}
```

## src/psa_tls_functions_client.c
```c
/*
 * Copyright (c) 2021 Nordic Semiconductor ASA.
 *
 * SPDX-License-Identifier: LicenseRef-Nordic-5-Clause
 */

#include <zephyr/logging/log.h>
LOG_MODULE_REGISTER(psa_tls_client);

#include <nrf.h>
#include <errno.h>
#include <zephyr/kernel.h>
#include <zephyr/net/socket.h>
#include <zephyr/net/net_core.h>
#include <zephyr/net/tls_credentials.h>
#include <zephyr/linker/sections.h>

#include "certificate.h"
#include "psa_tls_functions.h"
#include "psa_tls_credentials.h"

static char recv_buffer[RECV_BUFFER_SIZE]; /* Buffer for storing payload */


/** @brief Function for setting up the client socket to use for TLS handshake.
 *
 * @returns The socket identifier.
 */
static int setup_tls_client_socket(void)
{
	int err;
	int sock;
	int verify = TLS_PEER_VERIFY_REQUIRED;

	/* List of security tags to register. */
	sec_tag_t sec_tag_list[] = {
		CA_CERTIFICATE_TAG,
		PSK_TAG,
	};

#if defined(CONFIG_MBEDTLS_TLS_VERSION_1_3)
	sock = socket(AF_INET, SOCK_STREAM, IPPROTO_TLS_1_3);
#else
	sock = socket(AF_INET, SOCK_STREAM, IPPROTO_TLS_1_2);
#endif
	if (sock < 0) {
		LOG_ERR("Failed to create a socket. Err: %d", errno);
		return -errno;
	}

	err = setsockopt(sock, SOL_TLS, TLS_PEER_VERIFY,
			 &verify, sizeof(verify));
	if (err < 0) {
		LOG_ERR("Failed to set TLS peer verification. Err %d", errno);
		(void)close(sock);
		return -errno;
	}

	err = setsockopt(sock, SOL_TLS, TLS_SEC_TAG_LIST, sec_tag_list,
			 sizeof(sec_tag_list));
	if (err < 0) {
		LOG_ERR("Failed to set TLS security TAG list. Err: %d", errno);
		(void)close(sock);
		return -errno;
	}

	err = setsockopt(sock, SOL_TLS, TLS_HOSTNAME,
			 TLS_PEER_HOSTNAME, sizeof(TLS_PEER_HOSTNAME));
	if (err < 0) {
		LOG_ERR("Failed to set TLS_HOSTNAME option. Err: %d", errno);
		(void)close(sock);
		return -errno;
	}

	return sock;
}

/** @brief Thread function that handles all the steps of the TLS handshake for
 *  a client. Loops forever and connects on given port number.
 *
 */
void process_psa_tls(void)
{
	int ret;
	int sock;
	int received;
	struct sockaddr_in server_addr;
	socklen_t server_addr_len = sizeof(server_addr);

	server_addr.sin_family = AF_INET;
	server_addr.sin_port = htons(SERVER_PORT);
	inet_pton(AF_INET, CONFIG_NET_CONFIG_PEER_IPV4_ADDR,
		  &server_addr.sin_addr);

	while (true) {

		sock = setup_tls_client_socket();
		if (sock < 0) {
			LOG_INF("Retrying acquiring socket");
			k_sleep(K_MSEC(1000));
			continue;
		}

		LOG_INF("Initiates TLS connection on port %d ...",
			SERVER_PORT);
		ret = connect(sock, (struct sockaddr *)&server_addr,
			      server_addr_len);

		if (ret < 0) {
			LOG_WRN("Cannot make TLS connection. Err: %d", errno);
			LOG_INF("Will re-try connection in 1 second");
			(void)close(sock);
			k_sleep(K_MSEC(1000));
			continue;
		}
		LOG_INF("TLS handshake completed");

		while (true) {
			/* Try to receive data while connected */
			received = recv(sock, recv_buffer,
					sizeof(recv_buffer), 0);

			if (received == 0) {
				/* Connection closed */
				LOG_INF("TLS Connection closed");
				break;

			} else if (received < 0) {
				/* Socket error */
				LOG_ERR("TLS Connection error: %d", errno);
				break;
			}

			LOG_INF("TLS received %d byte(s)", received);

			ret = psa_tls_send_buffer(sock, recv_buffer, received);
			if (ret != 0) {
				LOG_ERR("TLS Failed to send. Err: %d", errno);
				break;
			}

			LOG_INF("TLS replied with %d bytes", received);
		}

		LOG_INF("Closing TLS connection");
		(void)close(sock);
	}
}
```

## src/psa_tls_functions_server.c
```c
/*
 * Copyright (c) 2021 Nordic Semiconductor ASA.
 *
 * SPDX-License-Identifier: LicenseRef-Nordic-5-Clause
 */

#include <zephyr/logging/log.h>
LOG_MODULE_REGISTER(psa_tls_server);

#include <nrf.h>
#include <errno.h>
#include <zephyr/kernel.h>
#include <zephyr/net/socket.h>
#include <zephyr/net/net_core.h>
#include <zephyr/net/tls_credentials.h>
#include <zephyr/linker/sections.h>

#include "certificate.h"
#include "psa_tls_functions.h"
#include "psa_tls_credentials.h"

static char recv_buffer[RECV_BUFFER_SIZE]; /* Buffer for storing payload */


/** @brief Function for setting up the server socket to use for TLS handshake.
 *
 * @returns The socket identifier.
 */
static int setup_tls_server_socket(void)
{
	int err;
	int sock;
	struct sockaddr_in my_addr;

	/* List of security tags to register. */
	sec_tag_t sec_tag_list[] = {
		SERVER_CERTIFICATE_TAG,
		PSK_TAG,
	};

	memset(&my_addr, 0, sizeof(my_addr));
	my_addr.sin_family = AF_INET;
	my_addr.sin_port = htons(SERVER_PORT);
#if defined(CONFIG_MBEDTLS_TLS_VERSION_1_3)
	sock = socket(my_addr.sin_family, SOCK_STREAM, IPPROTO_TLS_1_3);
#else
	sock = socket(my_addr.sin_family, SOCK_STREAM, IPPROTO_TLS_1_2);
#endif

	err = setsockopt(sock, SOL_TLS, TLS_SEC_TAG_LIST, sec_tag_list,
			 sizeof(sec_tag_list));
	if (err < 0) {
		LOG_ERR("Failed to set TLS security TAG list. Err: %d", errno);
		(void)close(sock);
		return -errno;
	}

	err = bind(sock, (struct sockaddr *)&my_addr, sizeof(my_addr));
	if (err < 0) {
		LOG_ERR("Failed to bind TLS socket. Err: %d", errno);
		(void)close(sock);
		return -errno;
	}

	err = listen(sock, MAX_CLIENT_QUEUE);
	if (err < 0) {
		LOG_ERR("Failed to listen on TLS socket. Err: %d", errno);
		(void)close(sock);
		return -errno;
	}

	return sock;
}

/** @brief Thread function that handles all the steps of the TLS handshake for
 *  a server. Loops forever and accepts connections on the given port number.
 *
 */
void process_psa_tls(void)
{
	int err;
	int sock;
	int client;
	int received;
	struct sockaddr_in client_addr;
	socklen_t client_addr_len = sizeof(client_addr);

retry:
	sock = setup_tls_server_socket();
	if (sock < 0) {
		LOG_INF("Retrying to create a socket");
		k_sleep(K_MSEC(1000));
		goto retry;
	}

	while (true) {
		LOG_INF("Waiting for TLS connection on port %d ...",
			SERVER_PORT);
		client = accept(sock, (struct sockaddr *)&client_addr,
				&client_addr_len);

		if (client < 0) {
			LOG_ERR("TLS accept error (%d)", -errno);
			(void)close(sock);
			k_sleep(K_MSEC(1000));
			goto retry;
		}

		LOG_INF("Accepted TLS connection");

		while (true) {
			/* Try to receive data while connected */
			received = recv(client, recv_buffer,
					sizeof(recv_buffer), 0);

			if (received == 0) {
				/* Connection closed */
				LOG_INF("TLS Connection closed");
				break;

			} else if (received < 0) {
				/* Socket error */
				LOG_ERR("TLS Connection error: %d", errno);
				break;
			}

			LOG_INF("TLS received %d bytes", received);

			err = psa_tls_send_buffer(client, recv_buffer, received);
			if (err != 0) {
				LOG_ERR("TLS Failed to send. Err: %d", errno);
				break;
			}

			LOG_INF("TLS replied with %d bytes", received);
		}

		LOG_INF("Closing TLS connection");
		(void)close(client);
	}
}
```
